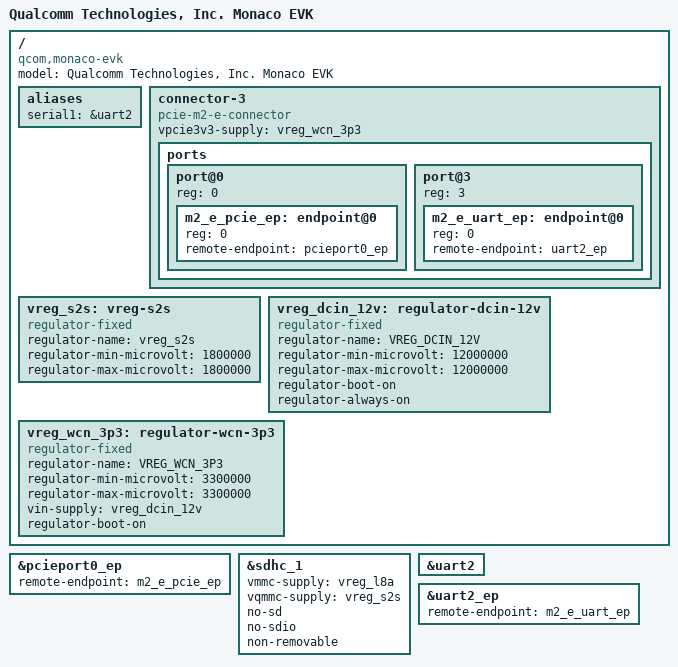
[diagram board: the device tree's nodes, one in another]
// SPDX-License-Identifier: BSD-3-Clause
/*
 * Copyright (c) Qualcomm Technologies, Inc. and/or its subsidiaries.
 */

/dts-v1/;

#include "monaco-evk-common.dtsi"

/ {
	model = "Qualcomm Technologies, Inc. Monaco EVK";
	compatible = "qcom,monaco-evk", "qcom,qcs8300";

	aliases {
		serial1 = &uart2;
	};

	connector-3 {
		compatible = "pcie-m2-e-connector";
		vpcie3v3-supply = <&vreg_wcn_3p3>;

		ports {
			#address-cells = <1>;
			#size-cells = <0>;

			port@0 {
				reg = <0>;
				#address-cells = <1>;
				#size-cells = <0>;

				m2_e_pcie_ep: endpoint@0 {
					reg = <0>;
					remote-endpoint = <&pcieport0_ep>;
				};
			};

			port@3 {
				reg = <3>;
				#address-cells = <1>;
				#size-cells = <0>;

				m2_e_uart_ep: endpoint@0 {
					reg = <0>;
					remote-endpoint = <&uart2_ep>;
				};
			};
		};
	};

	/* This comes from a PMIC handled within the SAIL domain */
	vreg_s2s: vreg-s2s {
		compatible = "regulator-fixed";
		regulator-name = "vreg_s2s";

		regulator-min-microvolt = <1800000>;
		regulator-max-microvolt = <1800000>;
	};

	vreg_dcin_12v: regulator-dcin-12v {
		compatible = "regulator-fixed";

		regulator-name = "VREG_DCIN_12V";
		regulator-min-microvolt = <12000000>;
		regulator-max-microvolt = <12000000>;

		regulator-boot-on;
		regulator-always-on;
	};

	vreg_wcn_3p3: regulator-wcn-3p3 {
		compatible = "regulator-fixed";

		regulator-name = "VREG_WCN_3P3";
		regulator-min-microvolt = <3300000>;
		regulator-max-microvolt = <3300000>;

		vin-supply = <&vreg_dcin_12v>;

		regulator-boot-on;
	};
};

&pcieport0_ep {
	remote-endpoint = <&m2_e_pcie_ep>;
};

&sdhc_1 {
	vmmc-supply = <&vreg_l8a>;
	vqmmc-supply = <&vreg_s2s>;

	no-sd;
	no-sdio;
	non-removable;

	status = "okay";
};

&uart2 {
	status = "okay";
};

&uart2_ep {
	remote-endpoint = <&m2_e_uart_ep>;
};
